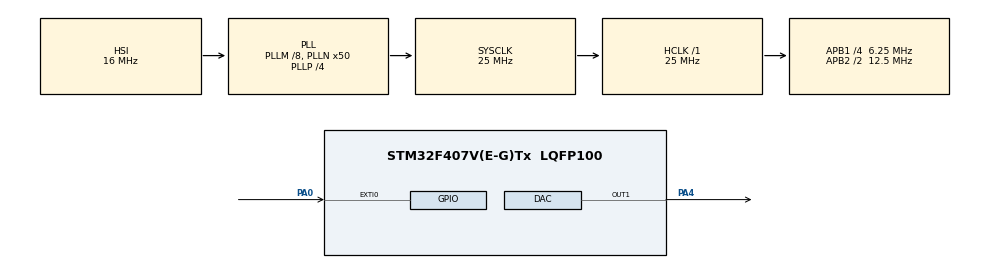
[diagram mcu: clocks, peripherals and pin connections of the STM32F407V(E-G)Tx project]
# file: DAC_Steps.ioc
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Mcu.Family=STM32F4
Mcu.Name=STM32F407V(E-G)Tx
Mcu.Package=LQFP100
NVIC.EXTI0_IRQn=true\:0\:1\:false\:false\:true\:true\:true
NVIC.PriorityGroup=NVIC_PRIORITYGROUP_0
PA0-WKUP.GPIO_ModeDefaultEXTI=GPIO_MODE_IT_RISING
PA0-WKUP.GPIO_PuPd=GPIO_PULLDOWN
PA0-WKUP.Signal=GPXTI0
PA13.Mode=Serial_Wire
PA13.Signal=SYS_JTMS-SWDIO
PA14.Mode=Serial_Wire
PA14.Signal=SYS_JTCK-SWCLK
PA4.Signal=COMP_DAC1_group
PH0-OSC_IN.Mode=HSE-External-Oscillator
PH0-OSC_IN.Signal=RCC_OSC_IN
PH1-OSC_OUT.Mode=HSE-External-Oscillator
PH1-OSC_OUT.Signal=RCC_OSC_OUT
ProjectManager.HeapSize=0x200
ProjectManager.StackSize=0x400
ProjectManager.TargetToolchain=STM32CubeIDE
RCC.48MHZClocksFreq_Value=14285714.285714285
RCC.AHBFreq_Value=25000000
RCC.APB1CLKDivider=RCC_HCLK_DIV4
RCC.APB1Freq_Value=6250000
RCC.APB1TimFreq_Value=12500000
RCC.APB2CLKDivider=RCC_HCLK_DIV2
RCC.APB2Freq_Value=12500000
RCC.APB2TimFreq_Value=25000000
RCC.CortexFreq_Value=25000000
RCC.HCLKFreq_Value=25000000
RCC.HSE_VALUE=8000000
RCC.HSI_VALUE=16000000
RCC.LSE_VALUE=32768
RCC.PLLM=8
RCC.PLLN=50
RCC.PLLP=RCC_PLLP_DIV4
RCC.PLLQ=7
RCC.SYSCLKFreq_VALUE=25000000
RCC.SYSCLKSource=RCC_SYSCLKSOURCE_PLLCLK
RCC.VCOOutputFreq_Value=100000000
SH.COMP_DAC1_group.0=DAC_OUT1,DAC_OUT1
board=STM32F407G-DISC1

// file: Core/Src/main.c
/* USER CODE BEGIN Header */
/**
  ******************************************************************************
  * @file           : main.c
  * @brief          : Main program body
  ******************************************************************************
  * @attention
  *
  * Copyright (c) 2021 STMicroelectronics.
  * All rights reserved.
  *
  * This software is licensed under terms that can be found in the LICENSE file
  * in the root directory of this software component.
  * If no LICENSE file comes with this software, it is provided AS-IS.
  *
  ******************************************************************************
  */
/* USER CODE END Header */
#include "main.h"

/* USER CODE BEGIN PM */
#define INP_VOL 2.0
#define STEP 400
/* USER CODE END PM */

DAC_HandleTypeDef hdac; // PA4
float frac = INP_VOL/3.0 ;
float vol=0.0;
uint32_t i = 0, val = 0;

void SystemClock_Config(void);
static void MX_GPIO_Init(void);
static void MX_DAC_Init(void);

int main(void)
{

  /* MCU Configuration--------------------------------------------------------*/

  /* Reset of all peripherals, Initializes the Flash interface and the Systick. */
  HAL_Init();

  /* Configure the system clock */
  SystemClock_Config();

  /* Initialize all configured peripherals */
  MX_GPIO_Init();
  MX_DAC_Init();

  /* Infinite loop */
  while (1)
  {

  }
}

void SystemClock_Config(void)
{
  RCC_OscInitTypeDef RCC_OscInitStruct = {0};
  RCC_ClkInitTypeDef RCC_ClkInitStruct = {0};

  /** Configure the main internal regulator output voltage
  */
  __HAL_RCC_PWR_CLK_ENABLE();
  __HAL_PWR_VOLTAGESCALING_CONFIG(PWR_REGULATOR_VOLTAGE_SCALE1);
  /** Initializes the RCC Oscillators according to the specified parameters
  * in the RCC_OscInitTypeDef structure.
  */
  RCC_OscInitStruct.OscillatorType = RCC_OSCILLATORTYPE_HSI;
  RCC_OscInitStruct.HSIState = RCC_HSI_ON;
  RCC_OscInitStruct.HSICalibrationValue = RCC_HSICALIBRATION_DEFAULT;
  RCC_OscInitStruct.PLL.PLLState = RCC_PLL_ON;
  RCC_OscInitStruct.PLL.PLLSource = RCC_PLLSOURCE_HSI;
  RCC_OscInitStruct.PLL.PLLM = 8;
  RCC_OscInitStruct.PLL.PLLN = 50;
  RCC_OscInitStruct.PLL.PLLP = RCC_PLLP_DIV4;
  RCC_OscInitStruct.PLL.PLLQ = 7;
  if (HAL_RCC_OscConfig(&RCC_OscInitStruct) != HAL_OK)
  {
    Error_Handler();
  }
  /** Initializes the CPU, AHB and APB buses clocks
  */
  RCC_ClkInitStruct.ClockType = RCC_CLOCKTYPE_HCLK|RCC_CLOCKTYPE_SYSCLK
                              |RCC_CLOCKTYPE_PCLK1|RCC_CLOCKTYPE_PCLK2;
  RCC_ClkInitStruct.SYSCLKSource = RCC_SYSCLKSOURCE_PLLCLK;
  RCC_ClkInitStruct.AHBCLKDivider = RCC_SYSCLK_DIV1;
  RCC_ClkInitStruct.APB1CLKDivider = RCC_HCLK_DIV4;
  RCC_ClkInitStruct.APB2CLKDivider = RCC_HCLK_DIV2;

  if (HAL_RCC_ClockConfig(&RCC_ClkInitStruct, FLASH_LATENCY_0) != HAL_OK)
  {
    Error_Handler();
  }
}

static void MX_DAC_Init(void)
{

  DAC_ChannelConfTypeDef sConfig = {0};

  /** DAC Initialization
  */
  hdac.Instance = DAC;
  if (HAL_DAC_Init(&hdac) != HAL_OK)
  {
    Error_Handler();
  }
  /** DAC channel OUT1 config
  */
  sConfig.DAC_Trigger = DAC_TRIGGER_NONE;
  sConfig.DAC_OutputBuffer = DAC_OUTPUTBUFFER_ENABLE;
  if (HAL_DAC_ConfigChannel(&hdac, &sConfig, DAC_CHANNEL_1) != HAL_OK)
  {
    Error_Handler();
  }
  /* USER CODE BEGIN DAC_Init 2 */
  HAL_DAC_Start(&hdac,DAC_CHANNEL_1 );
  /* USER CODE END DAC_Init 2 */

}

static void MX_GPIO_Init(void)
{
  GPIO_InitTypeDef GPIO_InitStruct = {0};

  /* GPIO Ports Clock Enable */
  __HAL_RCC_GPIOH_CLK_ENABLE();
  __HAL_RCC_GPIOA_CLK_ENABLE();

  /*Configure GPIO pin : PA0 */
  GPIO_InitStruct.Pin = GPIO_PIN_0;
  GPIO_InitStruct.Mode = GPIO_MODE_IT_RISING;
  GPIO_InitStruct.Pull = GPIO_PULLDOWN;
  HAL_GPIO_Init(GPIOA, &GPIO_InitStruct);

  /* EXTI interrupt init*/
  HAL_NVIC_SetPriority(EXTI0_IRQn, 0, 1);
  HAL_NVIC_EnableIRQ(EXTI0_IRQn);

}

/* USER CODE BEGIN 4 */
void HAL_GPIO_EXTI_Callback(uint16_t GPIO_Pin)
{
	if(GPIO_Pin == GPIO_PIN_0)
	{
	if(i>4000) i=0;
	i = i + STEP;
	val = (int)(frac*i);
	vol = (val/4096.0)*3.0;
	HAL_DAC_SetValue(&hdac, DAC_CHANNEL_1,DAC_ALIGN_12B_R , val);
	}
}
/* USER CODE END 4 */

void Error_Handler(void)
{
  __disable_irq();
  while (1)
  {
  }
}
